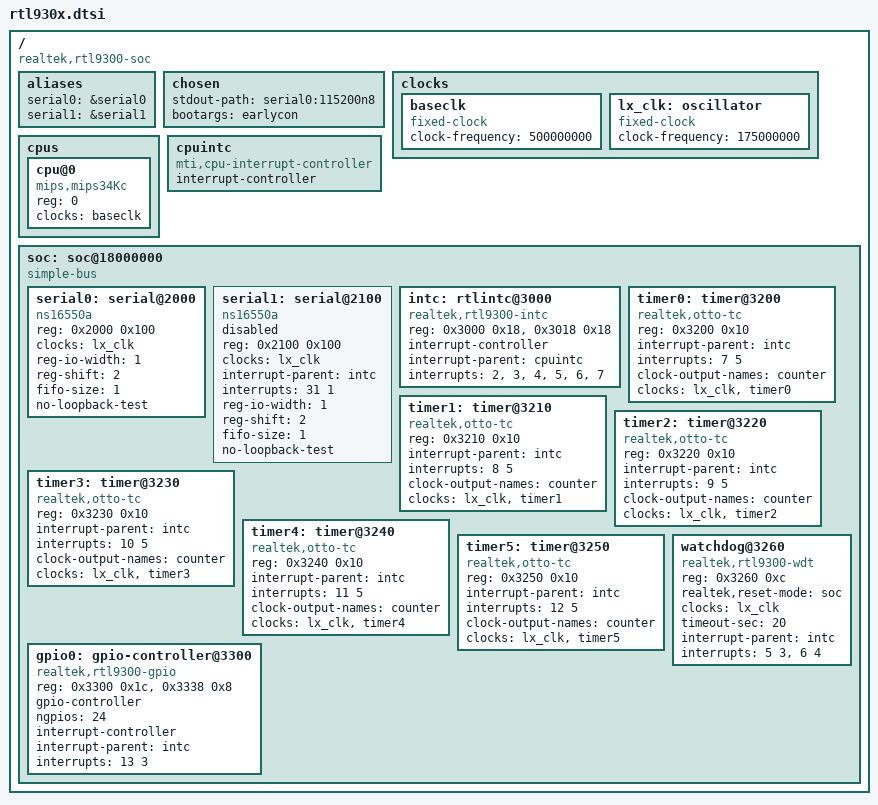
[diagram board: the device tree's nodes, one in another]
// SPDX-License-Identifier: GPL-2.0-or-later OR MIT

/dts-v1/;

/ {
	#address-cells = <1>;
	#size-cells = <1>;

	compatible = "realtek,rtl9300-soc";

	aliases {
		serial0 = &serial0;
		serial1 = &serial1;
	};

	chosen {
		stdout-path = "serial0:115200n8";
		bootargs = "earlycon";
	};

	clocks {
		baseclk: baseclk {
			compatible = "fixed-clock";
			#clock-cells = <0>;
			clock-frequency = <500000000>;
		};

		lx_clk: oscillator {
			compatible = "fixed-clock";
			#clock-cells = <0>;
			clock-frequency = <175000000>;
		};
	};

	cpus {
		#address-cells = <1>;
		#size-cells = <0>;

		cpu@0 {
			compatible = "mips,mips34Kc";
			reg = <0>;
			clocks = <&baseclk>;
		};
	};

	cpuintc: cpuintc {
		#address-cells = <0>;
		#interrupt-cells = <1>;
		interrupt-controller;
		compatible = "mti,cpu-interrupt-controller";
	};

	soc: soc@18000000 {
		compatible = "simple-bus";
		#address-cells = <1>;
		#size-cells = <1>;
		ranges = <0x0 0x18000000 0x10000>;

		serial0: serial@2000 {
			compatible = "ns16550a";
			reg = <0x2000 0x100>;

			clocks = <&lx_clk>;

//			interrupt-parent = <&intc>;
//			interrupts = <30 0>;

			reg-io-width = <1>;
			reg-shift = <2>;
			fifo-size = <1>;
			no-loopback-test;

			status = "okay";
		};

		serial1: serial@2100 {
			compatible = "ns16550a";
			reg = <0x2100 0x100>;

			clocks = <&lx_clk>;

			interrupt-parent = <&intc>;
			interrupts = <31 1>;

			reg-io-width = <1>;
			reg-shift = <2>;
			fifo-size = <1>;
			no-loopback-test;

			status = "disabled";
		};

		intc: rtlintc@3000 {
			compatible = "realtek,rtl9300-intc", "realtek,rtl-intc";
			reg = <0x3000 0x18>, <0x3018 0x18>;
			interrupt-controller;
			#interrupt-cells = <2>;

			interrupt-parent = <&cpuintc>;
			interrupts = <2>, <3>, <4>, <5>, <6>, <7>;
		};

		timer0: timer@3200 {
			compatible = "realtek,otto-tc";
			reg = <0x3200 0x10>;
			interrupt-parent = <&intc>;
			interrupts = <7 5>;
			#clock-cells = <0>;
			clock-output-names = "counter";
			clocks = <&lx_clk>, <&timer0>;
			clock-names = "bus", "counter";
		};

		timer1: timer@3210 {
			compatible = "realtek,otto-tc";
			reg = <0x3210 0x10>;
			interrupt-parent = <&intc>;
			interrupts = <8 5>;
			#clock-cells = <0>;
			clock-output-names = "counter";
			clocks = <&lx_clk>, <&timer1>;
			clock-names = "bus", "counter";
		};

		timer2: timer@3220 {
			compatible = "realtek,otto-tc";
			reg = <0x3220 0x10>;
			interrupt-parent = <&intc>;
			interrupts = <9 5>;
			#clock-cells = <0>;
			clock-output-names = "counter";
			clocks = <&lx_clk>, <&timer2>;
			clock-names = "bus", "counter";
		};

		timer3: timer@3230 {
			compatible = "realtek,otto-tc";
			reg = <0x3230 0x10>;
			interrupt-parent = <&intc>;
			interrupts = <10 5>;
			#clock-cells = <0>;
			clock-output-names = "counter";
			clocks = <&lx_clk>, <&timer3>;
			clock-names = "bus", "counter";
		};

		timer4: timer@3240 {
			compatible = "realtek,otto-tc";
			reg = <0x3240 0x10>;
			interrupt-parent = <&intc>;
			interrupts = <11 5>;
			#clock-cells = <0>;
			clock-output-names = "counter";
			clocks = <&lx_clk>, <&timer4>;
			clock-names = "bus", "counter";
		};

		timer5: timer@3250 {
			compatible = "realtek,otto-tc";
			reg = <0x3250 0x10>;
			interrupt-parent = <&intc>;
			interrupts = <12 5>;
			#clock-cells = <0>;
			clock-output-names = "counter";
			clocks = <&lx_clk>, <&timer5>;
			clock-names = "bus", "counter";
		};

		watchdog@3260 {
			compatible = "realtek,rtl9300-wdt";
			reg = <0x3260 0xc>;

			realtek,reset-mode = "soc";

			clocks = <&lx_clk>;
			timeout-sec = <20>;

			interrupt-parent = <&intc>;
			interrupt-names = "phase1", "phase2";
			interrupts = <5 3>, <6 4>;
		};

		gpio0: gpio-controller@3300 {
			compatible = "realtek,rtl9300-gpio", "realtek,otto-gpio";
			reg = <0x3300 0x1c>, <0x3338 0x8>;

			gpio-controller;
			#gpio-cells = <2>;
            ngpios = <24>;

			interrupt-controller;
			#interrupt-cells = <2>;

			interrupt-parent = <&intc>;
			interrupts = <13 3>;
		};
	};
};
